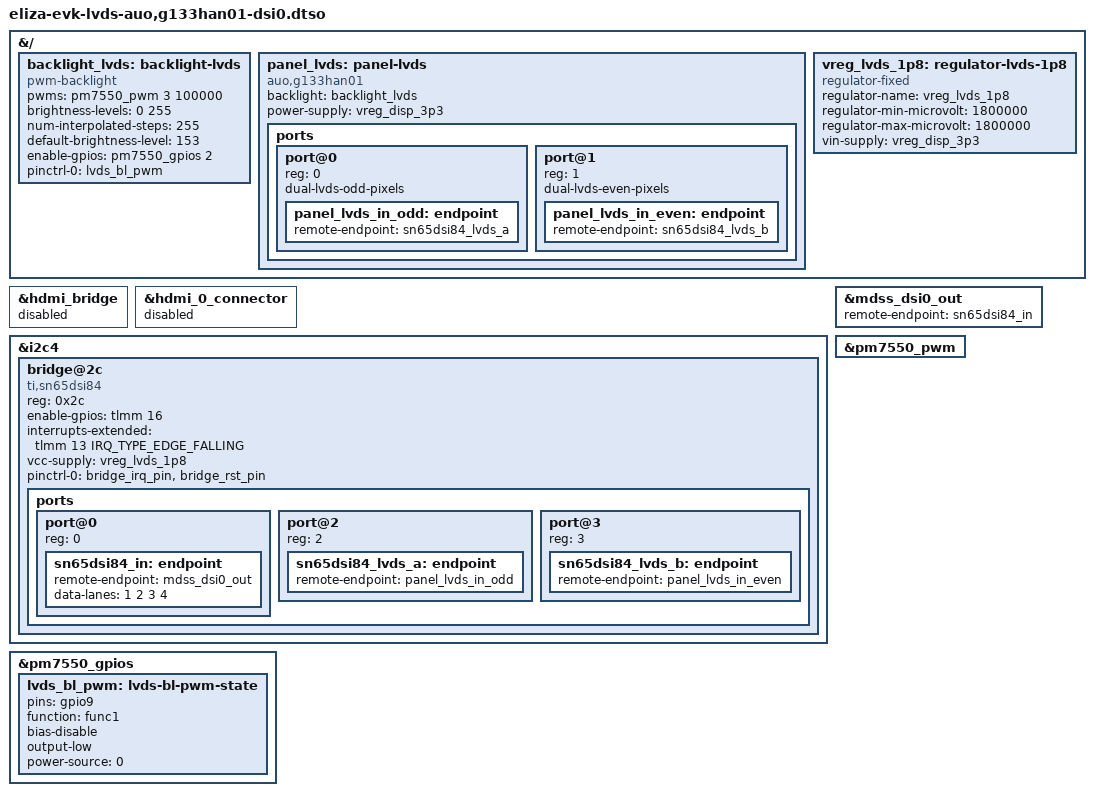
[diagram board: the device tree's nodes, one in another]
// SPDX-License-Identifier: BSD-3-Clause
/*
 * Copyright (c) Qualcomm Technologies, Inc. and/or its subsidiaries.
 */

/dts-v1/;
/plugin/;

#include <dt-bindings/gpio/gpio.h>
#include <dt-bindings/interrupt-controller/irq.h>

&{/} {
	backlight_lvds: backlight-lvds {
		compatible = "pwm-backlight";
		pwms = <&pm7550_pwm 3 100000>;
		brightness-levels = <0 255>;
		num-interpolated-steps = <255>;
		default-brightness-level = <153>;
		enable-gpios = <&pm7550_gpios 2 GPIO_ACTIVE_HIGH>;
		pinctrl-names = "default";
		pinctrl-0 = <&lvds_bl_pwm>;
	};

	panel_lvds: panel-lvds {
		compatible = "auo,g133han01";
		backlight = <&backlight_lvds>;
		power-supply = <&vreg_disp_3p3>;

		ports {
			#address-cells = <1>;
			#size-cells = <0>;

			port@0 {
				reg = <0>;
				dual-lvds-odd-pixels;
				panel_lvds_in_odd: endpoint {
					remote-endpoint = <&sn65dsi84_lvds_a>;
				};
			};

			port@1 {
				reg = <1>;
				dual-lvds-even-pixels;
				panel_lvds_in_even: endpoint {
					remote-endpoint = <&sn65dsi84_lvds_b>;
				};
			};
		};
	};

	vreg_lvds_1p8: regulator-lvds-1p8 {
		compatible = "regulator-fixed";
		regulator-name = "vreg_lvds_1p8";
		regulator-min-microvolt = <1800000>;
		regulator-max-microvolt = <1800000>;
		vin-supply = <&vreg_disp_3p3>;
	};
};

&hdmi_bridge {
	status = "disabled";
};

&hdmi_0_connector {
	status = "disabled";
};

&i2c4 {
	#address-cells = <1>;
	#size-cells = <0>;

	bridge@2c {
		compatible = "ti,sn65dsi84";
		reg = <0x2c>;
		enable-gpios = <&tlmm 16 GPIO_ACTIVE_HIGH>;
		interrupts-extended = <&tlmm 13 IRQ_TYPE_EDGE_FALLING>;
		vcc-supply = <&vreg_lvds_1p8>;
		pinctrl-0 = <&bridge_irq_pin>, <&bridge_rst_pin>;
		pinctrl-names = "default";

		ports {
			#address-cells = <1>;
			#size-cells = <0>;

			port@0 {
				reg = <0>;
				sn65dsi84_in: endpoint {
					remote-endpoint = <&mdss_dsi0_out>;
					data-lanes = <1 2 3 4>;
				};
			};

			port@2 {
				reg = <2>;
				sn65dsi84_lvds_a: endpoint {
					remote-endpoint = <&panel_lvds_in_odd>;
				};
			};

			port@3 {
				reg = <3>;
				sn65dsi84_lvds_b: endpoint {
					remote-endpoint = <&panel_lvds_in_even>;
				};
			};
		};
	};
};

&mdss_dsi0_out {
	remote-endpoint = <&sn65dsi84_in>;
};

&pm7550_gpios {
	lvds_bl_pwm: lvds-bl-pwm-state {
		pins = "gpio9";
		function = "func1";
		bias-disable;
		output-low;
		power-source = <0>;
	};
};

&pm7550_pwm {
	status = "okay";
};
